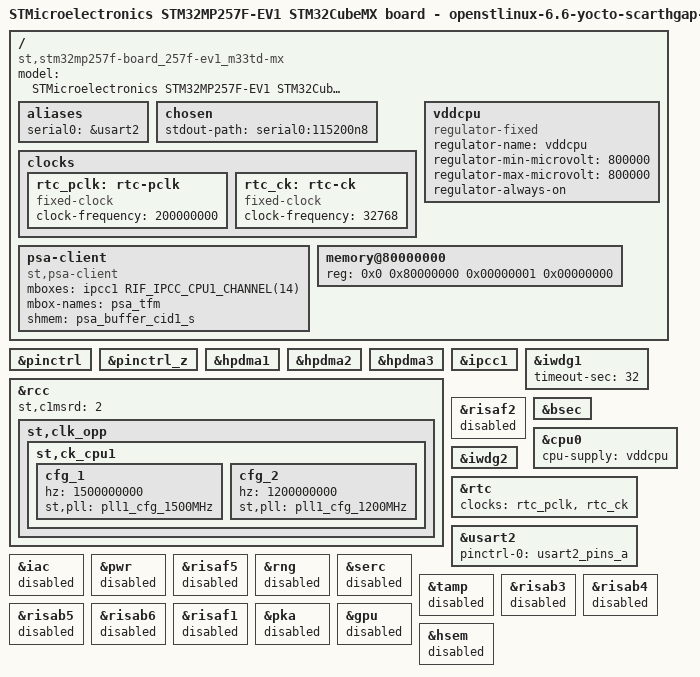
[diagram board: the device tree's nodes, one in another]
/dts-v1/;
#include <dt-bindings/pinctrl/stm32-pinfunc.h>
#include <dt-bindings/clock/stm32mp25-clksrc.h>
#include "stm32mp257.dtsi"
#include "stm32mp25xf.dtsi"
#include "stm32mp257f-board_257f-ev1_m33td-mx-rcc.dtsi"
#include "stm32mp257f-board_257f-ev1_m33td-mx-resmem.dtsi"
#include "stm32mp257f-board_257f-ev1_m33td-mx-rif.dtsi"

/* USER CODE BEGIN includes */
#include <dt-bindings/mfd/st,stpmic2.h>
#include <dt-bindings/regulator/st,stm32mp25-regulator.h>
#include <dt-bindings/reset/stm32mp25-resets.h>
#include <dt-bindings/soc/stm32mp25-rif.h>
#include <dt-bindings/soc/stm32mp25-risab.h>
#include <dt-bindings/soc/stm32mp25-risaf.h>
#include <dt-bindings/soc/stm32mp25-rifsc.h>
/* USER CODE END includes */

/{
	model = "STMicroelectronics STM32MP257F-EV1 STM32CubeMX board - openstlinux-6.6-yocto-scarthgap-mpu-v25.01.03";
	compatible = "st,stm32mp257f-board_257f-ev1_m33td-mx", "st,stm32mp257f-ev1", "st,stm32mp257";

	/* USER CODE BEGIN root */

	aliases{
		serial0 = &usart2;
	};

	chosen{
		stdout-path = "serial0:115200n8";
	};

	clocks{

		rtc_pclk:rtc-pclk{
			compatible = "fixed-clock";
			#clock-cells = <0>;
			clock-frequency = <200000000>;
		};

		rtc_ck:rtc-ck{
			compatible = "fixed-clock";
			#clock-cells = <0>;
			clock-frequency = <32768>;
		};
	};

	vddcpu:vddcpu{
		compatible = "regulator-fixed";
		regulator-name = "vddcpu";
		regulator-min-microvolt = <800000>;
		regulator-max-microvolt = <800000>;
		regulator-always-on;
	};

	psa-client{
		compatible = "st,psa-client";
		mboxes = <&ipcc1 RIF_IPCC_CPU1_CHANNEL(14)>;
		mbox-names = "psa_tfm";
		shmem = <&psa_buffer_cid1_s>;
	};
	/* USER CODE END root */

	memory@80000000{
		device_type = "memory";
		reg = <0x0 0x80000000 0x00000001 0x00000000>;
	};
};

&pinctrl {
	/* USER CODE BEGIN pinctrl */
	/* USER CODE END pinctrl */
};

&pinctrl_z {
	/* USER CODE BEGIN pinctrl_z */
	/* USER CODE END pinctrl_z */
};

&hpdma1 {
	status = "okay";
};

&hpdma2 {
	status = "okay";
};

&hpdma3 {
	status = "okay";
};

&ipcc1 {
	status = "okay";
};

&iwdg1 {
	status = "okay";

	/* USER CODE BEGIN iwdg1 */
	timeout-sec = <32>;
	/* USER CODE END iwdg1 */
};

&rcc {
	status = "okay";

	/* USER CODE BEGIN rcc */
	st,c1msrd = <2>;

	st,clk_opp{

		st,ck_cpu1{

			cfg_1{
				hz = <1500000000>;
				st,pll = <&pll1_cfg_1500MHz>;
			};

			cfg_2{
				hz = <1200000000>;
				st,pll = <&pll1_cfg_1200MHz>;
			};
		};
	};
	/* USER CODE END rcc */
};

&risaf2 {
	status = "okay";
};

/* USER CODE BEGIN addons */

&bsec {
	status = "okay";
};

&cpu0 {
	cpu-supply = <&vddcpu>;
};

&iwdg2 {
	/delete-property/ resets;
};

&rtc {
	clocks = <&rtc_pclk>, <&rtc_ck>;
	status = "okay";
};

&usart2 {
	pinctrl-names = "default";
	pinctrl-0 = <&usart2_pins_a>;
	status = "okay";
};
&iac {
	status = "disabled";
};

&pwr {
	status = "disabled";
};

&risaf5 {
	status = "disabled";
};

&rng {
	status = "disabled";
};

&serc {
	status = "disabled";
};

&tamp {
	status = "disabled";
};

&risaf2 {
 	status = "disabled";
};

&risab3 {
 	status = "disabled";
};

&risab4 {
 	status = "disabled";
};

&risab5 {
 	status = "disabled";
 };

&risab6 {
 	status = "disabled";
};

&risaf1 {
 	status = "disabled";
};
&pka {
 	status = "disabled";
};
&gpu {
	status = "disabled";
};

&hsem {
	status = "disabled";
};
/* USER CODE END addons */
